# ESP32-S2 register map
Vendor: ESPRESSIF SYSTEMS (SHANGHAI) CO., LTD.; Series: ESP32 S-Series; File version: 20
CPU: Xtensa LX7 r0p0, little endian, no MPU, no FPU, 0 interrupt priority bits
Address unit: 32 bits
Registers are 32-bit, read-write, reset 0x0 unless marked. A register's access mark holds for its fields unless they carry their own. Offsets are from the block's base; [hi:lo] are bit positions; {n}, {i} and the like mark numbered series.

## SYSTIMER — System Timer
Base 0x3F423000
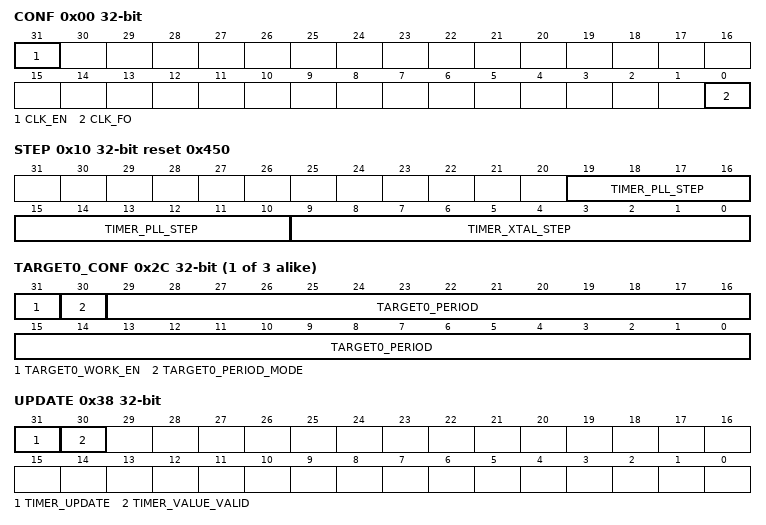
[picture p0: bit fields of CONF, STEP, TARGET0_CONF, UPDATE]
0x00 CONF — Configure system timer clock
  [31] CLK_EN — Register clock enable.
  [0] CLK_FO — System timer clock force enable.
0x04 LOAD wo — Load value to system timer
  [31] TIMER_LOAD — Set this bit to 1, the value stored in SYSTIMER_TIMER_LOAD_HI and in SYSTIMER_TIMER_LOAD_LO will be loaded to system timer
0x08 LOAD_HI — High 32 bits to be loaded to system timer
  [31:0] TIMER_LOAD_HI — The value to be loaded into system timer, high 32 bits.
0x0C LOAD_LO — Low 32 bits to be loaded to system timer
  [31:0] TIMER_LOAD_LO — The value to be loaded into system timer, low 32 bits.
0x10 STEP reset 0x450 — System timer accumulation step
  [19:10] TIMER_PLL_STEP — Set system timer increment step when using PLL_CLK
  [9:0] TIMER_XTAL_STEP — Set system timer increment step when using XTAL_CLK.
{0x14+8i} TARGET{i}_HI (i=0..2) — System timer target {i}, high 32 bits
  [31:0] TIMER_TARGET{i}_HI — System timer target {i}, high 32 bits.
{0x18+8i} TARGET{i}_LO (i=0..2) — System timer target {i}, low 32 bits
  [31:0] TIMER_TARGET{i}_LO — System timer target {i}, low 32 bits.
{0x2C+4i} TARGET{i}_CONF (i=0..2) — Configure work mode for system timer target {i}
  [31] TARGET{i}_WORK_EN — System timer target {i} work enable.
  [30] TARGET{i}_PERIOD_MODE — Set work mode for system timer target {i}. 0: work in a timedelay alarm mode; 1: work in periodic alarms mode.
  [29:0] TARGET{i}_PERIOD — Set alarm period for system timer target {i}, only valid in periodic alarms mode.
0x38 UPDATE access per field — Read out system timer value
  [31] TIMER_UPDATE wo — Update system timer value to registers.
  [30] TIMER_VALUE_VALID ro — Check if it is valid to read out timer value from registers. 0: Not ready to read timer value from registers; 1: Ready to read timer value from registers
0x3C VALUE_HI ro — System timer value, high 32 bits
  [31:0] TIMER_VALUE_HI — System timer value, high 32 bits.
0x40 VALUE_LO ro — System timer value, low 32 bits
  [31:0] TIMER_VALUE_LO — System timer value, low 32 bits.
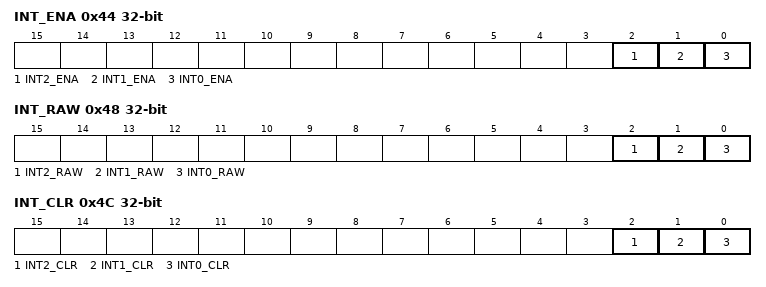
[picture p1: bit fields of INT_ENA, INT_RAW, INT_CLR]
0x44 INT_ENA — System timer interrupt enable
  [2] INT2_ENA — Interrupt enable bit of system timer target 2.
  [1] INT1_ENA — Interrupt enable bit of system timer target 1.
  [0] INT0_ENA — Interrupt enable bit of system timer target 0.
0x48 INT_RAW ro — System timer interrupt raw
  [2] INT2_RAW — Interrupt raw bit of system timer target 2.
  [1] INT1_RAW — Interrupt raw bit of system timer target 1.
  [0] INT0_RAW — Interrupt raw bit of system timer target 0.
0x4C INT_CLR wo — System timer interrupt clear
  [2] INT2_CLR — Interrupt clear bit of system timer target 2.
  [1] INT1_CLR — Interrupt clear bit of system timer target 1.
  [0] INT0_CLR — Interrupt clear bit of system timer target 0.
0xFC DATE reset 0x1807160 — Version control register

## USB_WRAP — USB_WRAP Peripheral
Base 0x3F439000
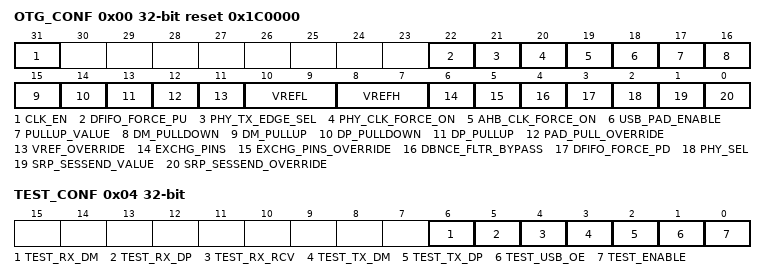
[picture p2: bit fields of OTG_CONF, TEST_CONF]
0x00 OTG_CONF reset 0x1C0000 — USB OTG Wrapper Configure Register
  [31] CLK_EN — Disable auto clock gating of CSR registers
  [22] DFIFO_FORCE_PU — Disable the dfifo to go into low power mode. The data in dfifo will not lost.
  [21] PHY_TX_EDGE_SEL — Select phy tx signal output clock edge. 1'b0: negedge. 1'b1: posedge.
  [20] PHY_CLK_FORCE_ON — Force phy clock always on
  [19] AHB_CLK_FORCE_ON — Force ahb clock always on
  [18] USB_PAD_ENABLE — Enable USB pad function
  [17] PULLUP_VALUE — Controlle pullup value. 1'b0: typical value is 2.4K. 1'b1: typical value is 1.2K.
  [16] DM_PULLDOWN — Controlle USB D+ pulldown
  [15] DM_PULLUP — Controlle USB D+ pullup
  [14] DP_PULLDOWN — Controlle USB D+ pulldown
  [13] DP_PULLUP — Controlle USB D+ pullup
  [12] PAD_PULL_OVERRIDE — Enable software controlle USB D+ D- pullup pulldown
  [11] VREF_OVERRIDE — Enable software controlle input threshold
  [10:9] VREFL — Control single-end input low threshold,0.8V to 1.04V, step 80mV
  [8:7] VREFH — Control single-end input high threshold,1.76V to 2V, step 80mV
  [6] EXCHG_PINS — USB D+ D- exchange. 1'b0: don't change. 1'b1: exchange D+ D-
  [5] EXCHG_PINS_OVERRIDE — Enable software controlle USB D+ D- exchange
  [4] DBNCE_FLTR_BYPASS — Bypass Debounce filters for avalid,bvalid,vbusvalid,session end, id signals
  [3] DFIFO_FORCE_PD — Force the dfifo to go into low power mode. The data in dfifo will not lost.
  [2] PHY_SEL — Select internal external PHY. 1'b0: Select internal PHY. 1'b1: Select external PHY.
  [1] SRP_SESSEND_VALUE — Software over-ride value of srp session end signal.
  [0] SRP_SESSEND_OVERRIDE — This bit is used to enable the software over-ride of srp session end signal. 1'b0: the signal is controlled by the chip input. 1'b1: the signal is controlled by the software.
0x04 TEST_CONF access per field — USB Internal PHY Testing Register
  [6] TEST_RX_DM ro — USB D- rx value in test
  [5] TEST_RX_DP ro — USB D+ rx value in test
  [4] TEST_RX_RCV ro — USB differential rx value in test
  [3] TEST_TX_DM rw — USB D- tx value in test
  [2] TEST_TX_DP rw — USB D+ tx value in test
  [1] TEST_USB_OE rw — USB pad oen in test
  [0] TEST_ENABLE rw — Enable test of the USB pad
0x3FC DATE reset 0x2102010 — Version Control Register
  [31:0] USB_WRAP_DATE — Date register

## XTS_AES — XTS-AES-128 Flash Encryption
Base 0x6003A100
{0x100+4i} PLAIN_{i} (i=0..15) — Plaintext register {i}
  [31:0] PLAIN — This register stores %sth 32-bit piece of plaintext.
0x140 LINESIZE — Configures the size of target memory space
  [1:0] LINESIZE — Configures the data size of a single encryption. 0: 128 bits. 1: 256 bits. 2: 512 bits.
0x144 DESTINATION — Configures the type of the external memory
  [0] DESTINATION — Configures the type of the external memory. Currently, it must be set to 0, as the Manual Encryption block only supports flash encryption. Errors may occur if users write 1. 0: flash. 1: external RAM.
0x148 PHYSICAL_ADDRESS
  [29:0] PHYSICAL_ADDRESS
0x14C TRIGGER wo — Activates AES algorithm
  [0] TRIGGER — Set to enable manual encryption.
0x150 RELEASE wo — Release control
  [0] RELEASE — Set to grant SPI1 access to encrypted result.
0x154 DESTROY wo — Destroys control
  [0] DESTROY — Set to destroy encrypted result.
0x158 STATE ro — Status register
  [1:0] STATE — Indicates the status of the Manual Encryption block. 0x0 (XTS_AES_IDLE): idle. 0x1 (XTS_AES_BUSY): busy with encryption. 0x2 (XTS_AES_DONE): encryption is completed, but the encrypted result is not accessible to SPI. 0X3 (XTS_AES_RELEASE): encrypted result is accessible to SPI.
0x15C DATE ro reset 0x20190514 — Version control register
  [29:0] DATE — Version control register.
